# Snowbird2 register map
File version: 1.0
Anyka AK1090
Registers are 32-bit, access not given, no defined reset value unless marked. A register's access mark holds for its fields unless they carry their own. Offsets are from the block's base; lines under a group give offsets from that group; [hi:lo] are bit positions; {n}, {i} and the like mark numbered series; 'fields as' and 'values as' point back to an identical list; <NAME> marks a mode.

## Memory map
0x04000000 CONFIG size 0x200
0x04010000 L2 size 0x200
0x0401C000 TBD size 0x100
0x04036000 UART size 0x10
0x0404A000 NFC size 0x200
0x0405B000 ECC size 0x10 — meaning tbc
0x04070000 USB size 0x400
0x04080000 DACS size 0x100
0x04090000 ADCS size 0x100
0x040A0000 SPI size 0x100

## CONFIG
Base 0x04000000
0x00 REG_CHIP_ID — holds the chip ID
0x04 REG_CLOCK_DIV1
0x08 REG_CLOCK_DIV2
0x0C REG_CLOCK_RST_EN
0x10 REG_DACS_HCLK
0x10 REG_DACS_HCLK
0x14 REG_IMG_SENSOR_CFG
0x18 REG_TIMER1_CTRL
0x1C REG_TIMER2_CTRL
0x20 REG_RTC_CTRL
0x24 REG_RTC_READ_VAL
0x28 REG_ADCS_CHANNEL
0x2C REG_PWM0_CTRL
0x30 REG_PWM1_CTRL
0x34 REG_INT_IRQ
0x38 REG_INT_FIQ
0x3C REG_WGPIO_POL
0x40 REG_WGPIO_CLR
0x44 REG_WGPIO_EN
0x48 REG_WGPIO_STA
0x4C REG_INT_SYSCTL
0x50 REG_POWER_CTRL
0x54 REG_BOOTUP_MODE
0x58 REG_MUL_FUNC_CTRL
0x5C REG_ANALOG_CTRL1
0x60 REG_USB_REG_CFG
{0x5C+4i} REG_ANALOG_CTRL{i} (i=2..4)
0x70 REG_ADC1_STA
0x74 REG_SHARE_PIN_CTRL
0x78 REG_ANALOG_CTRL5
0x7C REG_GPIO_DIR_1
0x80 REG_GPIO_OUT_1
0x84 REG_GPIO_DIR_2
0x88 REG_GPIO_OUT_2
0x8C REG_PMU_CTRL1
0x90 REG_PMU_CTRL2
0x94 REG_ADC1_CFG
0x98 REG_INT_ANALOG
0x9C REG_GPIO_PULL_UD_1
0xA4 REG_EFUSE_CTRL
0xA8 REG_EFUSE_READ_DATA1
0xAC REG_EFUSE_READ_DATA2
0xBC REG_GPIO_IN_1
0xC0 REG_GPIO_IN_2
0xCC REG_INT_STA
0xE0 REG_GPIO_INT_EN_1
0xE4 REG_GPIO_INT_EN_2
0xF0 REG_0x40000f0 — unknown purpose
0xF4 REG_0x40000f4 — unknown purpose
0x104 REG_TIMER2_CNT

## L2
Base 0x04010000
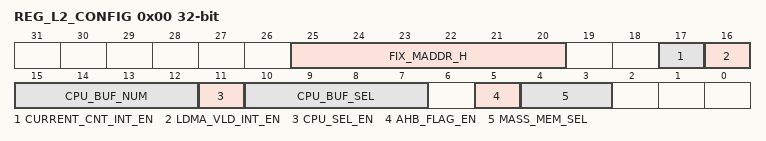
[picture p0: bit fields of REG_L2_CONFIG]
0x00 REG_L2_CONFIG
  [25:20] FIX_MADDR_H — Upper RAM limit (RAM beyond this is used for UART buffers etc.
  [17] CURRENT_CNT_INT_EN
  [16] LDMA_VLD_INT_EN
  [15:12] CPU_BUF_NUM
  [11] CPU_SEL_EN
  [10:7] CPU_BUF_SEL
  [5] AHB_FLAG_EN — Enable the Advanced High-Performance Bus
  [4:3] MASS_MEM_SEL
0x04 REG_L2_LDMA_SRC
0x08 REG_L2_LDMA_DEST
0x0C REG_L2_LDMA_COUNT
0x10 REG_L2_BUFFER_STATUS_1
0x14 REG_L2_PAGE_DIRTY_FLAG_1
0x18 REG_L2_PAGE_DIRTY_FLAG_2
0x1C REG_L2_PAGE_CURRENT_COUNT
{0x1C+4i} REG_L2_BUFFER_CONFIG_{i} (i=1..3)
0x2C REG_L2_BUFFER_ENABLE
0x30 REG_L2_BUFFER_STATUS_2
0x120 REG_L2_PAGE_LIFE_COUNT1
{0x11C+4i} REG_L2_PAGE_LIFE_COUNT{i} (i=1..40)

## TBD
Base 0x0401C000
0x00 REG_TBD_SOMETHING

## UART
Base 0x04036000
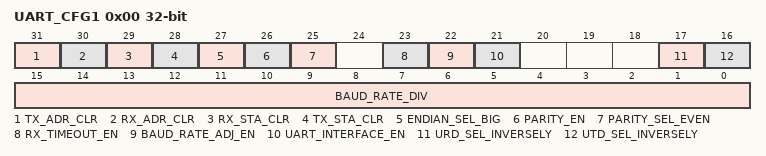
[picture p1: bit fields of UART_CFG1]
0x00 UART_CFG1
  [31] TX_ADR_CLR, [30] RX_ADR_CLR, [29] RX_STA_CLR, [28] TX_STA_CLR, [27] ENDIAN_SEL_BIG, [26] PARITY_EN, [25] PARITY_SEL_EVEN, [23] RX_TIMEOUT_EN, [22] BAUD_RATE_ADJ_EN, [21] UART_INTERFACE_EN, [17] URD_SEL_INVERSELY, [16] UTD_SEL_INVERSELY, [15:0] BAUD_RATE_DIV
0x04 UART_CFG2
0x08 UART_DATA_CFG
0x0C UART_BUF_TRSHLD

## NFC
Base 0x0404A000
0x00 REG_NFC_COMMAND
0x04 REG_NFC_ECC_MODE
{0x4+4i} REG_NFC_SOMETHING{i} (i=1..4)
0x50 REG_NFC_DATA1
0x54 REG_NFC_DATA2
0x58 REG_NFC_STATUS — unclear meaning
0x5C REG_NFC_CMD_LEN
0x60 REG_NFC_DATA_LEN
0x68 REG_NFC_RAND_ENC — NFC randomizer (encoder)
0x6C REG_NFC_RAND_DEC — NFC randomizer (decoder)
{0x100+4i} REG_NFC_REG{i} (i=0..24)

## ECC — meaning tbc
Base 0x0405B000
0x00 REG_ECC_CTRL
0x04 REG_ECC_MODE
0x08 REG_ECC_RESULT

## USB
Base 0x04070000
0x00 REG_USB_FADDR 8-bit
0x01 REG_USB_POWER 8-bit
0x02 REG_USB_INTRTX1 8-bit
0x03 REG_USB_INTRTX2 8-bit
0x04 REG_USB_INTRRX1 8-bit
0x05 REG_USB_INTRRX2 8-bit
0x06 USB_REG_INTRTX1E 16-bit
0x08 USB_REG_INTRRX1E 16-bit
0x0A REG_USB_INTRUSB 8-bit
0x0B REG_USB_TBD4 8-bit
0x0E REG_USB_INDEX 8-bit
0x0F REG_USB_TESEMODE 8-bit
0x10 REG_USB_TXMAXP0/TXMAXP1 16-bit
0x12 REG_USB_CSR0/TXCSR1 8-bit
0x13 REG_USB_CSR02/TXCSR2 8-bit
0x14 REG_USB_RXMAXP1 16-bit
0x16 REG_USB_RXCSR1 8-bit
0x17 REG_USB_RXCSR2 8-bit
0x18 REG_USB_COUNT0 8-bit
0x19 REG_USB_RXCOUNT2
0x1F REG_USB_FIFOSIZE
{0x20+4i} REG_USB_FIFO_EP{i} (i=0..3)
0x200 REG_USB_SOMETHING_1
0x204 REG_USB_DMA_CNTL_1
0x208 REG_USB_DMA_ADDR_1
0x20C REG_USB_SOMETHING_4
0x214 REG_USB_DMA_CNTL_2
0x218 REG_USB_DMA_ADDR_2
{0x330+4i} REG_USB_EP{i}_TX_COUNT (i=0..2)
0x33C REG_USB_FORBID_WRITE_REG
0x340 REG_USB_START_PRE_READ_REG
0x348 REG_USB_FS_SPEED_REG

## DACS
Base 0x04080000
0x00 REG_DACS_CFG
0x04 REG_I2S_CFG
0x08 REG_DACS_DATA

## ADCS
Base 0x04090000
0x00 REG_ADCS_CTRL
0x04 REG_ADCS_RX_DATA1
0x08 REG_ADCS_RX_DATA2

## SPI
Base 0x040A0000
0x00 REG_SPI_CTRL
0x04 REG_SPI_STA
0x08 REG_SPI_INT_EN
0x0C REG_SPI_DATA_CNT
0x10 REG_SPI_TX_EXBUF
0x14 REG_SPI_RX_EXBUF
0x18 REG_SPI_TX_INBUF
0x1C REG_SPI_RX_INBUF
0x20 REG_SPI_RX_TO
0x24 REG_SPI_TX_DLY
